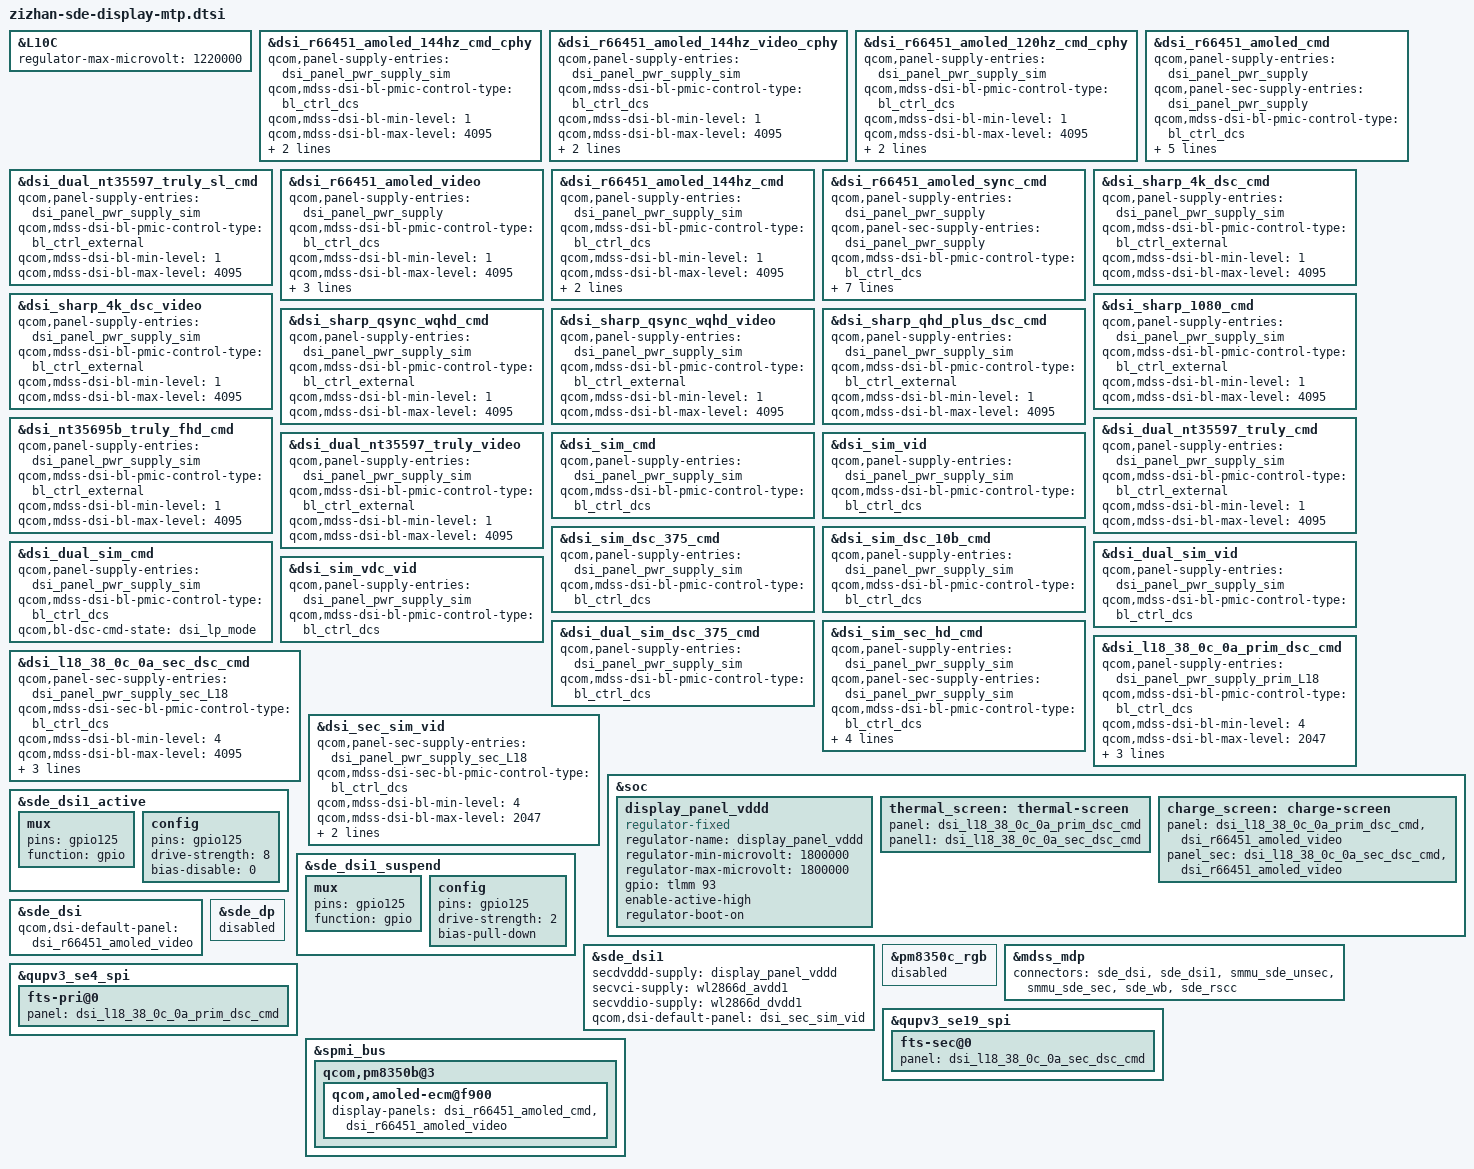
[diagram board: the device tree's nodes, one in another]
#include "waipio-sde-display.dtsi"

&L10C {
    regulator-max-microvolt = <1220000>;
};

&dsi_r66451_amoled_144hz_cmd_cphy {
	qcom,panel-supply-entries = <&dsi_panel_pwr_supply_sim>;
	qcom,mdss-dsi-bl-pmic-control-type = "bl_ctrl_dcs";
	qcom,mdss-dsi-bl-min-level = <1>;
	qcom,mdss-dsi-bl-max-level = <4095>;
	qcom,mdss-brightness-max-level = <255>;
	qcom,mdss-dsi-bl-inverted-dbv;
};

&dsi_r66451_amoled_144hz_video_cphy {
	qcom,panel-supply-entries = <&dsi_panel_pwr_supply_sim>;
	qcom,mdss-dsi-bl-pmic-control-type = "bl_ctrl_dcs";
	qcom,mdss-dsi-bl-min-level = <1>;
	qcom,mdss-dsi-bl-max-level = <4095>;
	qcom,mdss-brightness-max-level = <255>;
	qcom,mdss-dsi-bl-inverted-dbv;
};

&dsi_r66451_amoled_120hz_cmd_cphy {
	qcom,panel-supply-entries = <&dsi_panel_pwr_supply_sim>;
	qcom,mdss-dsi-bl-pmic-control-type = "bl_ctrl_dcs";
	qcom,mdss-dsi-bl-min-level = <1>;
	qcom,mdss-dsi-bl-max-level = <4095>;
	qcom,mdss-brightness-max-level = <255>;
	qcom,mdss-dsi-bl-inverted-dbv;
};

&dsi_r66451_amoled_cmd {
	qcom,panel-supply-entries = <&dsi_panel_pwr_supply>;
	qcom,panel-sec-supply-entries = <&dsi_panel_pwr_supply>;
	qcom,mdss-dsi-bl-pmic-control-type = "bl_ctrl_dcs";
	qcom,mdss-dsi-bl-min-level = <1>;
	qcom,mdss-dsi-bl-max-level = <4095>;
	qcom,mdss-brightness-max-level = <255>;
	qcom,mdss-dsi-bl-inverted-dbv;
	qcom,platform-reset-gpio = <&tlmm 0 0>;
};

&dsi_dual_nt35597_truly_sl_cmd {
	qcom,panel-supply-entries = <&dsi_panel_pwr_supply_sim>;
	qcom,mdss-dsi-bl-pmic-control-type = "bl_ctrl_external";
	qcom,mdss-dsi-bl-min-level = <1>;
	qcom,mdss-dsi-bl-max-level = <4095>;
};

&dsi_r66451_amoled_video {
	qcom,panel-supply-entries = <&dsi_panel_pwr_supply>;
	qcom,mdss-dsi-bl-pmic-control-type = "bl_ctrl_dcs";
	qcom,mdss-dsi-bl-min-level = <1>;
	qcom,mdss-dsi-bl-max-level = <4095>;
	qcom,mdss-brightness-max-level = <255>;
	qcom,mdss-dsi-bl-inverted-dbv;
	qcom,platform-reset-gpio = <&tlmm 0 0>;
};

&dsi_r66451_amoled_144hz_cmd {
	qcom,panel-supply-entries = <&dsi_panel_pwr_supply_sim>;
	qcom,mdss-dsi-bl-pmic-control-type = "bl_ctrl_dcs";
	qcom,mdss-dsi-bl-min-level = <1>;
	qcom,mdss-dsi-bl-max-level = <4095>;
	qcom,mdss-brightness-max-level = <255>;
	qcom,mdss-dsi-bl-inverted-dbv;
};

&dsi_r66451_amoled_sync_cmd {
	qcom,panel-supply-entries = <&dsi_panel_pwr_supply>;
	qcom,panel-sec-supply-entries = <&dsi_panel_pwr_supply>;
	qcom,mdss-dsi-bl-pmic-control-type = "bl_ctrl_dcs";
	qcom,mdss-dsi-sec-bl-pmic-control-type = "bl_ctrl_dcs";
	qcom,mdss-dsi-bl-min-level = <1>;
	qcom,mdss-dsi-bl-max-level = <4095>;
	qcom,mdss-brightness-max-level = <255>;
	qcom,mdss-dsi-bl-inverted-dbv;
	qcom,platform-reset-gpio = <&tlmm 0 0>;
};

&dsi_sharp_4k_dsc_cmd {
	qcom,panel-supply-entries = <&dsi_panel_pwr_supply_sim>;
	qcom,mdss-dsi-bl-pmic-control-type = "bl_ctrl_external";
	qcom,mdss-dsi-bl-min-level = <1>;
	qcom,mdss-dsi-bl-max-level = <4095>;
};

&dsi_sharp_4k_dsc_video {
	qcom,panel-supply-entries = <&dsi_panel_pwr_supply_sim>;
	qcom,mdss-dsi-bl-pmic-control-type = "bl_ctrl_external";
	qcom,mdss-dsi-bl-min-level = <1>;
	qcom,mdss-dsi-bl-max-level = <4095>;
};

&dsi_sharp_1080_cmd {
	qcom,panel-supply-entries = <&dsi_panel_pwr_supply_sim>;
	qcom,mdss-dsi-bl-pmic-control-type = "bl_ctrl_external";
	qcom,mdss-dsi-bl-min-level = <1>;
	qcom,mdss-dsi-bl-max-level = <4095>;
};

&dsi_sharp_qsync_wqhd_cmd {
	qcom,panel-supply-entries = <&dsi_panel_pwr_supply_sim>;
	qcom,mdss-dsi-bl-pmic-control-type = "bl_ctrl_external";
	qcom,mdss-dsi-bl-min-level = <1>;
	qcom,mdss-dsi-bl-max-level = <4095>;
};

&dsi_sharp_qsync_wqhd_video {
	qcom,panel-supply-entries = <&dsi_panel_pwr_supply_sim>;
	qcom,mdss-dsi-bl-pmic-control-type = "bl_ctrl_external";
	qcom,mdss-dsi-bl-min-level = <1>;
	qcom,mdss-dsi-bl-max-level = <4095>;
};

&dsi_sharp_qhd_plus_dsc_cmd {
	qcom,panel-supply-entries = <&dsi_panel_pwr_supply_sim>;
	qcom,mdss-dsi-bl-pmic-control-type = "bl_ctrl_external";
	qcom,mdss-dsi-bl-min-level = <1>;
	qcom,mdss-dsi-bl-max-level = <4095>;
};

&dsi_nt35695b_truly_fhd_cmd {
	qcom,panel-supply-entries = <&dsi_panel_pwr_supply_sim>;
	qcom,mdss-dsi-bl-pmic-control-type = "bl_ctrl_external";
	qcom,mdss-dsi-bl-min-level = <1>;
	qcom,mdss-dsi-bl-max-level = <4095>;
};

&dsi_dual_nt35597_truly_cmd {
	qcom,panel-supply-entries = <&dsi_panel_pwr_supply_sim>;
	qcom,mdss-dsi-bl-pmic-control-type = "bl_ctrl_external";
	qcom,mdss-dsi-bl-min-level = <1>;
	qcom,mdss-dsi-bl-max-level = <4095>;
};

&dsi_dual_nt35597_truly_video {
	qcom,panel-supply-entries = <&dsi_panel_pwr_supply_sim>;
	qcom,mdss-dsi-bl-pmic-control-type = "bl_ctrl_external";
	qcom,mdss-dsi-bl-min-level = <1>;
	qcom,mdss-dsi-bl-max-level = <4095>;
};

&dsi_sim_cmd {
	qcom,panel-supply-entries = <&dsi_panel_pwr_supply_sim>;
	qcom,mdss-dsi-bl-pmic-control-type = "bl_ctrl_dcs";
};

&dsi_sim_vid {
	qcom,panel-supply-entries = <&dsi_panel_pwr_supply_sim>;
	qcom,mdss-dsi-bl-pmic-control-type = "bl_ctrl_dcs";
};

&dsi_sim_dsc_375_cmd {
	qcom,panel-supply-entries = <&dsi_panel_pwr_supply_sim>;
	qcom,mdss-dsi-bl-pmic-control-type = "bl_ctrl_dcs";
};

&dsi_sim_dsc_10b_cmd {
	qcom,panel-supply-entries = <&dsi_panel_pwr_supply_sim>;
	qcom,mdss-dsi-bl-pmic-control-type = "bl_ctrl_dcs";
};

&dsi_dual_sim_cmd {
	qcom,panel-supply-entries = <&dsi_panel_pwr_supply_sim>;
	qcom,mdss-dsi-bl-pmic-control-type = "bl_ctrl_dcs";
	qcom,bl-dsc-cmd-state = "dsi_lp_mode";
};

&dsi_dual_sim_vid {
	qcom,panel-supply-entries = <&dsi_panel_pwr_supply_sim>;
	qcom,mdss-dsi-bl-pmic-control-type = "bl_ctrl_dcs";
};

&dsi_sim_vdc_vid {
	qcom,panel-supply-entries = <&dsi_panel_pwr_supply_sim>;
	qcom,mdss-dsi-bl-pmic-control-type = "bl_ctrl_dcs";
};

&dsi_dual_sim_dsc_375_cmd {
	qcom,panel-supply-entries = <&dsi_panel_pwr_supply_sim>;
	qcom,mdss-dsi-bl-pmic-control-type = "bl_ctrl_dcs";
};

&dsi_sim_sec_hd_cmd {
	qcom,panel-supply-entries = <&dsi_panel_pwr_supply_sim>;
	qcom,panel-sec-supply-entries = <&dsi_panel_pwr_supply_sim>;
	qcom,mdss-dsi-bl-pmic-control-type = "bl_ctrl_dcs";
	qcom,mdss-dsi-sec-bl-pmic-control-type = "bl_ctrl_dcs";
	qcom,mdss-dsi-bl-min-level = <1>;
	qcom,mdss-dsi-bl-max-level = <1023>;
};

&dsi_l18_38_0c_0a_prim_dsc_cmd {
	qcom,panel-supply-entries = <&dsi_panel_pwr_supply_prim_L18>;
	qcom,mdss-dsi-bl-pmic-control-type = "bl_ctrl_dcs";
	qcom,mdss-dsi-bl-min-level = <4>;
	qcom,mdss-dsi-bl-max-level = <2047>;
	qcom,mdss-brightness-max-level = <2047>;
	qcom,mdss-brightness-init-level = <307>;
	qcom,platform-reset-gpio = <&tlmm 0 0>;
};

&dsi_l18_38_0c_0a_sec_dsc_cmd {
	qcom,panel-sec-supply-entries = <&dsi_panel_pwr_supply_sec_L18>;
	qcom,mdss-dsi-sec-bl-pmic-control-type = "bl_ctrl_dcs";
	qcom,mdss-dsi-bl-min-level = <4>;
	qcom,mdss-dsi-bl-max-level = <4095>;
	qcom,mdss-brightness-max-level = <4095>;
	qcom,mdss-brightness-init-level = <307>;
	qcom,platform-sec-reset-gpio = <&tlmm 125 0>;
};

&dsi_sec_sim_vid {
	qcom,panel-sec-supply-entries = <&dsi_panel_pwr_supply_sec_L18>;
	qcom,mdss-dsi-sec-bl-pmic-control-type = "bl_ctrl_dcs";
	qcom,mdss-dsi-bl-min-level = <4>;
	qcom,mdss-dsi-bl-max-level = <2047>;
	qcom,mdss-brightness-max-level = <2047>;
	qcom,platform-sec-reset-gpio = <&tlmm 125 0>;
};

&soc {
	display_panel_vddd: display_panel_vddd {
		compatible = "regulator-fixed";
		regulator-name = "display_panel_vddd";
		regulator-min-microvolt = <1800000>;
		regulator-max-microvolt = <1800000>;
		gpio = <&tlmm 93 0>;
		enable-active-high;
		regulator-boot-on;
	};
};

&sde_dsi1_active {
	mux {
		pins = "gpio125";
		function = "gpio";
	};

	config {
		pins = "gpio125";
		drive-strength = <8>;
		bias-disable = <0>;
	};
};

&sde_dsi1_suspend {
	mux {
		pins = "gpio125";
		function = "gpio";
	};

	config {
		pins = "gpio125";
		drive-strength = <2>;
		bias-pull-down;
	};
};

&sde_dsi {
	qcom,dsi-default-panel = <&dsi_r66451_amoled_video>;
};

&sde_dsi1 {
	secdvddd-supply = <&display_panel_vddd>;
	secvci-supply = <&wl2866d_avdd1>;
	secvddio-supply = <&wl2866d_dvdd1>;
	qcom,dsi-default-panel = <&dsi_sec_sim_vid>;
};

&sde_dp {
       status = "disabled";
};

&pm8350c_rgb {
       status = "disabled";
};

&mdss_mdp {
        connectors = <&sde_dsi &sde_dsi1 &smmu_sde_unsec &smmu_sde_sec &sde_wb &sde_rscc>;
 };

&qupv3_se4_spi {
	fts-pri@0 {
		panel = <&dsi_l18_38_0c_0a_prim_dsc_cmd>;
	};
};

&qupv3_se19_spi {
	fts-sec@0 {
		panel = <&dsi_l18_38_0c_0a_sec_dsc_cmd>;
	};
};

&soc {
	thermal_screen: thermal-screen {
		panel = <&dsi_l18_38_0c_0a_prim_dsc_cmd>;
		panel1 = <&dsi_l18_38_0c_0a_sec_dsc_cmd>;
        };
	charge_screen: charge-screen {
		panel  = <&dsi_l18_38_0c_0a_prim_dsc_cmd
				&dsi_r66451_amoled_video>;
		panel_sec = <&dsi_l18_38_0c_0a_sec_dsc_cmd
				&dsi_r66451_amoled_video>;
        };
};

&spmi_bus {
	qcom,pm8350b@3 {
		qcom,amoled-ecm@f900 {
			display-panels = <&dsi_r66451_amoled_cmd
					&dsi_r66451_amoled_video>;
		};
	};
};
